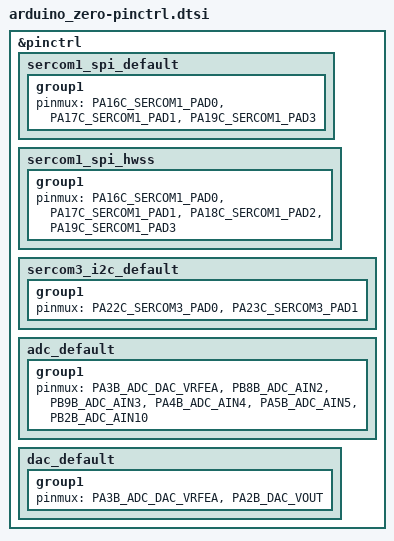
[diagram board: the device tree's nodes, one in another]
/*
 * Copyright (c) 2024 TiaC Systems
 * SPDX-License-Identifier: Apache-2.0
 */

#include <dt-bindings/pinctrl/samd21-da1gXabcd-pinctrl.h>

&pinctrl {
	sercom1_spi_default: sercom1_spi_default {		/* missing upstream */
		group1 {
			pinmux = <PA16C_SERCOM1_PAD0>,		/* SPI:COPI */
				 <PA17C_SERCOM1_PAD1>,		/* SPI:SCK */
				 <PA19C_SERCOM1_PAD3>;		/* SPI:CIPO */
		};
	};

	sercom1_spi_hwss: sercom1_spi_hwss {			/* missing upstream */
		group1 {
			pinmux = <PA16C_SERCOM1_PAD0>,		/* SPI:COPI */
				 <PA17C_SERCOM1_PAD1>,		/* SPI:SCK */
				 <PA18C_SERCOM1_PAD2>,		/* SPI:SS */
				 <PA19C_SERCOM1_PAD3>;		/* SPI:CIPO */
		};
	};

	sercom3_i2c_default: sercom3_i2c_default {		/* missing upstream */
		group1 {
			pinmux = <PA22C_SERCOM3_PAD0>,		/* I2C:SDA */
				 <PA23C_SERCOM3_PAD1>;		/* I2C:SCL */
		};
	};

	adc_default: adc_default {				/* missing upstream */
		group1 {
			pinmux = <PA3B_ADC_DAC_VRFEA>,
				 <PB8B_ADC_AIN2>,
				 <PB9B_ADC_AIN3>,
				 <PA4B_ADC_AIN4>,
				 <PA5B_ADC_AIN5>,
				 <PB2B_ADC_AIN10>;
		};
	};

	dac_default: dac_default {
		group1 {
			pinmux = <PA3B_ADC_DAC_VRFEA>,		/* missing upstream */
				 <PA2B_DAC_VOUT>;
		};
	};
};
